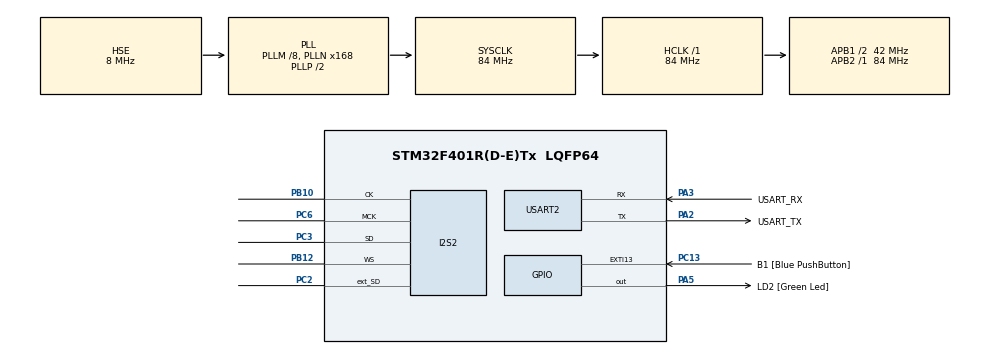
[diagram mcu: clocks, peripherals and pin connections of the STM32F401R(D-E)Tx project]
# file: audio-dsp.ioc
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Dma.I2S2_EXT_RX.0.Direction=DMA_PERIPH_TO_MEMORY
Dma.I2S2_EXT_RX.0.FIFOMode=DMA_FIFOMODE_DISABLE
Dma.I2S2_EXT_RX.0.Instance=DMA1_Stream3
Dma.I2S2_EXT_RX.0.MemDataAlignment=DMA_MDATAALIGN_HALFWORD
Dma.I2S2_EXT_RX.0.MemInc=DMA_MINC_ENABLE
Dma.I2S2_EXT_RX.0.Mode=DMA_CIRCULAR
Dma.I2S2_EXT_RX.0.PeriphDataAlignment=DMA_PDATAALIGN_HALFWORD
Dma.I2S2_EXT_RX.0.PeriphInc=DMA_PINC_DISABLE
Dma.I2S2_EXT_RX.0.Priority=DMA_PRIORITY_HIGH
Dma.Request0=I2S2_EXT_RX
Dma.Request1=SPI2_TX
Dma.SPI2_TX.1.Direction=DMA_MEMORY_TO_PERIPH
Dma.SPI2_TX.1.FIFOMode=DMA_FIFOMODE_DISABLE
Dma.SPI2_TX.1.Instance=DMA1_Stream4
Dma.SPI2_TX.1.MemDataAlignment=DMA_MDATAALIGN_HALFWORD
Dma.SPI2_TX.1.MemInc=DMA_MINC_ENABLE
Dma.SPI2_TX.1.Mode=DMA_CIRCULAR
Dma.SPI2_TX.1.PeriphDataAlignment=DMA_PDATAALIGN_HALFWORD
Dma.SPI2_TX.1.PeriphInc=DMA_PINC_DISABLE
Dma.SPI2_TX.1.Priority=DMA_PRIORITY_HIGH
I2S2.AudioFreq=I2S_AUDIOFREQ_48K
I2S2.DataFormat=I2S_DATAFORMAT_24B
I2S2.ErrorAudioFreq=-2.34 %
I2S2.FullDuplexMode=I2S_FULLDUPLEXMODE_ENABLE
I2S2.Instance=SPI$Index
I2S2.RealAudioFreq=46.875 KHz
I2S2.Standard=I2S_STANDARD_PHILIPS
I2S2.VirtualMode=I2S_MODE_MASTER
Mcu.Family=STM32F4
Mcu.Name=STM32F401R(D-E)Tx
Mcu.Package=LQFP64
NVIC.DMA1_Stream3_IRQn=true\:0\:0\:false\:false\:true\:false\:true
NVIC.DMA1_Stream4_IRQn=true\:0\:0\:false\:false\:true\:false\:true
NVIC.PriorityGroup=NVIC_PRIORITYGROUP_0
NVIC.SPI2_IRQn=true\:0\:0\:false\:false\:true\:true\:true
PA13.GPIO_Label=TMS
PA13.Mode=Serial_Wire
PA13.Signal=SYS_JTMS-SWDIO
PA14.GPIO_Label=TCK
PA14.Mode=Serial_Wire
PA14.Signal=SYS_JTCK-SWCLK
PA2.GPIO_Label=USART_TX
PA2.GPIO_Mode=GPIO_MODE_AF_PP
PA2.GPIO_PuPd=GPIO_NOPULL
PA2.GPIO_Speed=GPIO_SPEED_FREQ_LOW
PA2.Mode=Asynchronous
PA2.Signal=USART2_TX
PA3.GPIO_Label=USART_RX
PA3.GPIO_Mode=GPIO_MODE_AF_PP
PA3.GPIO_PuPd=GPIO_NOPULL
PA3.GPIO_Speed=GPIO_SPEED_FREQ_LOW
PA3.Mode=Asynchronous
PA3.Signal=USART2_RX
PA5.GPIO_Label=LD2 [Green Led]
PA5.GPIO_Mode=GPIO_MODE_OUTPUT_PP
PA5.GPIO_PuPd=GPIO_NOPULL
PA5.GPIO_Speed=GPIO_SPEED_FREQ_LOW
PA5.Signal=GPIO_Output
PB10.GPIO_Speed=GPIO_SPEED_FREQ_VERY_HIGH
PB10.Mode=Full_Duplex_Master
PB10.Signal=I2S2_CK
PB12.GPIO_Speed=GPIO_SPEED_FREQ_VERY_HIGH
PB12.Mode=Full_Duplex_Master
PB12.Signal=I2S2_WS
PB3.GPIO_Label=SWO
PB3.Signal=SYS_JTDO-SWO
PC13-ANTI_TAMP.GPIO_Label=B1 [Blue PushButton]
PC13-ANTI_TAMP.GPIO_ModeDefaultEXTI=GPIO_MODE_IT_FALLING
PC13-ANTI_TAMP.GPIO_PuPd=GPIO_NOPULL
PC13-ANTI_TAMP.Signal=GPXTI13
PC14-OSC32_IN.Mode=LSE-External-Oscillator
PC14-OSC32_IN.Signal=RCC_OSC32_IN
PC15-OSC32_OUT.Mode=LSE-External-Oscillator
PC15-OSC32_OUT.Signal=RCC_OSC32_OUT
PC2.Mode=Full_Duplex_Master
PC2.Signal=I2S2_ext_SD
PC3.GPIO_Speed=GPIO_SPEED_FREQ_VERY_HIGH
PC3.Mode=Full_Duplex_Master
PC3.Signal=I2S2_SD
PC6.GPIO_Speed=GPIO_SPEED_FREQ_VERY_HIGH
PC6.Mode=Master_Clock_Activated
PC6.Signal=I2S2_MCK
PH0\ -\ OSC_IN.Mode=HSE-External-Clock-Source
PH0\ -\ OSC_IN.Signal=RCC_OSC_IN
PH1\ -\ OSC_OUT.Mode=HSE-External-Clock-Source
PH1\ -\ OSC_OUT.Signal=RCC_OSC_OUT
ProjectManager.HeapSize=0x200
ProjectManager.StackSize=0x400
ProjectManager.TargetToolchain=STM32CubeIDE
RCC.48MHZClocksFreq_Value=24000000
RCC.AHBFreq_Value=84000000
RCC.APB1CLKDivider=RCC_HCLK_DIV2
RCC.APB1Freq_Value=42000000
RCC.APB1TimFreq_Value=84000000
RCC.APB2Freq_Value=84000000
RCC.APB2TimFreq_Value=84000000
RCC.CortexFreq_Value=84000000
RCC.HCLKFreq_Value=84000000
RCC.HSE_VALUE=8000000
RCC.HSI_VALUE=16000000
RCC.PLLI2SN=384
RCC.PLLM=8
RCC.PLLN=168
RCC.PLLQ=7
RCC.PLLSourceVirtual=RCC_PLLSOURCE_HSE
RCC.SYSCLKFreq_VALUE=84000000
RCC.SYSCLKSource=RCC_SYSCLKSOURCE_PLLCLK
RCC.VCOOutputFreq_Value=168000000
USART2.VirtualMode=VM_ASYNC
board=NUCLEO-F401RE

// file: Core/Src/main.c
/* USER CODE BEGIN Header */
/**
  ******************************************************************************
  * @file           : main.c
  * @brief          : Main program body
  ******************************************************************************
  * @attention
  *
  * <h2><center>&copy; Copyright (c) 2022 STMicroelectronics.
  * All rights reserved.</center></h2>
  *
  * This software component is licensed by ST under BSD 3-Clause license,
  * the "License"; You may not use this file except in compliance with the
  * License. You may obtain a copy of the License at:
  *                        opensource.org/licenses/BSD-3-Clause
  *
  ******************************************************************************
  */
/* USER CODE END Header */
#include "main.h"
#include "dma.h"
#include "i2s.h"
#include "usart.h"
#include "gpio.h"

/* USER CODE BEGIN Includes */
#include "AudioPasstrough.h"

/* USER CODE END Includes */

void SystemClock_Config(void);

int main(void)
{

  /* MCU Configuration--------------------------------------------------------*/

  /* Reset of all peripherals, Initializes the Flash interface and the Systick. */
  HAL_Init();

  /* Configure the system clock */
  SystemClock_Config();

  /* Initialize all configured peripherals */
  MX_DMA_Init(); // Hint: STM32CubeMx calls these functions in the wrong order (--> DMA not working with unmodified init)
  MX_GPIO_Init();
  MX_I2S2_Init();
  MX_USART2_UART_Init();

  /* USER CODE BEGIN 2 */

  AudioPassthrough_Init();

  /* USER CODE END 2 */

  /* Infinite loop */
  while (1)
  {

  }
}

void SystemClock_Config(void)
{
  RCC_OscInitTypeDef RCC_OscInitStruct = {0};
  RCC_ClkInitTypeDef RCC_ClkInitStruct = {0};

  /** Configure the main internal regulator output voltage
  */
  __HAL_RCC_PWR_CLK_ENABLE();
  __HAL_PWR_VOLTAGESCALING_CONFIG(PWR_REGULATOR_VOLTAGE_SCALE2);
  /** Initializes the RCC Oscillators according to the specified parameters
  * in the RCC_OscInitTypeDef structure.
  */
  RCC_OscInitStruct.OscillatorType = RCC_OSCILLATORTYPE_HSE;
  RCC_OscInitStruct.HSEState = RCC_HSE_BYPASS;
  RCC_OscInitStruct.PLL.PLLState = RCC_PLL_ON;
  RCC_OscInitStruct.PLL.PLLSource = RCC_PLLSOURCE_HSE;
  RCC_OscInitStruct.PLL.PLLM = 8;
  RCC_OscInitStruct.PLL.PLLN = 168;
  RCC_OscInitStruct.PLL.PLLP = RCC_PLLP_DIV2;
  RCC_OscInitStruct.PLL.PLLQ = 7;
  if (HAL_RCC_OscConfig(&RCC_OscInitStruct) != HAL_OK)
  {
    Error_Handler();
  }
  /** Initializes the CPU, AHB and APB buses clocks
  */
  RCC_ClkInitStruct.ClockType = RCC_CLOCKTYPE_HCLK|RCC_CLOCKTYPE_SYSCLK
                              |RCC_CLOCKTYPE_PCLK1|RCC_CLOCKTYPE_PCLK2;
  RCC_ClkInitStruct.SYSCLKSource = RCC_SYSCLKSOURCE_PLLCLK;
  RCC_ClkInitStruct.AHBCLKDivider = RCC_SYSCLK_DIV1;
  RCC_ClkInitStruct.APB1CLKDivider = RCC_HCLK_DIV2;
  RCC_ClkInitStruct.APB2CLKDivider = RCC_HCLK_DIV1;

  if (HAL_RCC_ClockConfig(&RCC_ClkInitStruct, FLASH_LATENCY_2) != HAL_OK)
  {
    Error_Handler();
  }
}

void Error_Handler(void)
{
  __disable_irq();
  while (1)
  {
  }
}

/************************ (C) COPYRIGHT STMicroelectronics *****END OF FILE****/
